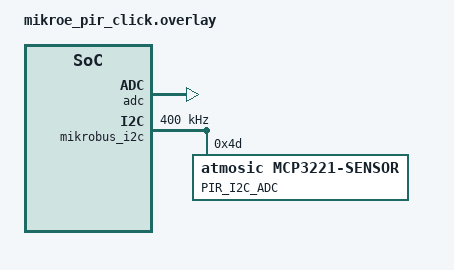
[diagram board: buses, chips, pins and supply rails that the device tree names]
/*
 * Copyright (c) 2025-2026 Atmosic
 *
 * SPDX-License-Identifier: LicenseRef-Atmosic
 */

/*
 * GADC Configuration for PIR Click
 * Uses existing ADC channel 7 configuration from board DTS
 */
&adc {
	status = "okay";
};

/*
 * I2C Configuration for PIR Click
 * MCP3221 12-bit ADC for alternative PIR sensor reading via I2C
 */
&mikrobus_i2c {
	status = "okay";
	clock-frequency = <I2C_BITRATE_FAST>;

	mcp3221: mcp3221@4d {
		compatible = "atmosic,mcp3221-sensor";
		reg = <0x4d>;
		label = "PIR_I2C_ADC";
		status = "okay";
	};
};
